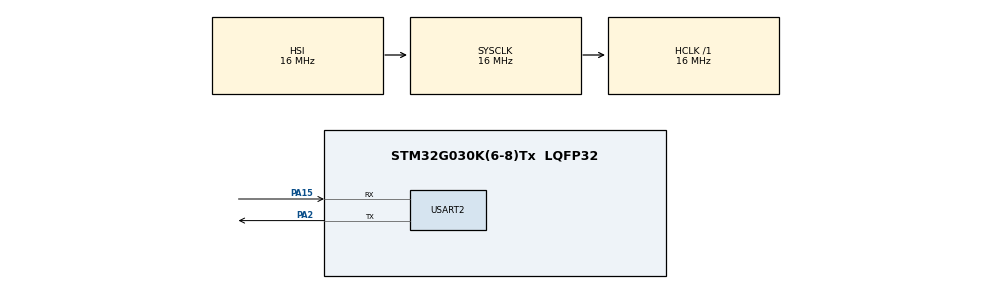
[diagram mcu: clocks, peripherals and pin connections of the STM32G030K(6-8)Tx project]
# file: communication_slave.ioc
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Dma.Request0=USART2_RX
Dma.USART2_RX.0.Direction=DMA_PERIPH_TO_MEMORY
Dma.USART2_RX.0.EventEnable=DISABLE
Dma.USART2_RX.0.Instance=DMA1_Channel1
Dma.USART2_RX.0.MemDataAlignment=DMA_MDATAALIGN_BYTE
Dma.USART2_RX.0.MemInc=DMA_MINC_ENABLE
Dma.USART2_RX.0.Mode=DMA_CIRCULAR
Dma.USART2_RX.0.PeriphDataAlignment=DMA_PDATAALIGN_BYTE
Dma.USART2_RX.0.PeriphInc=DMA_PINC_DISABLE
Dma.USART2_RX.0.Polarity=HAL_DMAMUX_REQ_GEN_RISING
Dma.USART2_RX.0.Priority=DMA_PRIORITY_HIGH
Dma.USART2_RX.0.RequestNumber=1
Dma.USART2_RX.0.SignalID=NONE
Dma.USART2_RX.0.SyncEnable=DISABLE
Dma.USART2_RX.0.SyncPolarity=HAL_DMAMUX_SYNC_NO_EVENT
Dma.USART2_RX.0.SyncRequestNumber=1
Dma.USART2_RX.0.SyncSignalID=NONE
Mcu.Family=STM32G0
Mcu.Name=STM32G030K(6-8)Tx
Mcu.Package=LQFP32
NVIC.DMA1_Channel1_IRQn=true\:0\:0\:false\:false\:true\:false\:true\:true
PA15.Mode=Asynchronous
PA15.Signal=USART2_RX
PA2.Mode=Asynchronous
PA2.Signal=USART2_TX
ProjectManager.HeapSize=0x200
ProjectManager.StackSize=0x400
ProjectManager.TargetToolchain=STM32CubeIDE
RCC.AHBFreq_Value=16000000
RCC.CortexFreq_Value=16000000
RCC.EXTERNAL_CLOCK_VALUE=12288000
RCC.HCLKFreq_Value=16000000
RCC.HSE_VALUE=8000000
RCC.HSI_VALUE=16000000
RCC.LSE_VALUE=32768
RCC.SYSCLKFreq_VALUE=16000000
RCC.VCOOutputFreq_Value=128000000
USART2.VirtualMode-Asynchronous=VM_ASYNC
board=custom

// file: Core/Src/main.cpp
/* USER CODE BEGIN Header */
/**
  ******************************************************************************
  * @file           : main.c
  * @brief          : Main program body
  ******************************************************************************
  * @attention
  *
  * Copyright (c) 2024 STMicroelectronics.
  * All rights reserved.
  *
  * This software is licensed under terms that can be found in the LICENSE file
  * in the root directory of this software component.
  * If no LICENSE file comes with this software, it is provided AS-IS.
  *
  ******************************************************************************
  */
/* USER CODE END Header */
#include "main.h"

UART_HandleTypeDef huart2;
DMA_HandleTypeDef hdma_usart2_rx;

/* USER CODE BEGIN PV */
static uint8_t rxBuf[128];
uint8_t receiveArray[11] = {0};
uint8_t read[6] = {0};
uint16_t angle = 0;
uint8_t speed = 0;

/* USER CODE END PV */

void SystemClock_Config(void);
static void MX_GPIO_Init(void);
static void MX_DMA_Init(void);
static void MX_USART2_UART_Init(void);
/* USER CODE BEGIN PFP */
void receiveData();

/* USER CODE END PFP */

int main(void)
{

  /* MCU Configuration--------------------------------------------------------*/

  /* Reset of all peripherals, Initializes the Flash interface and the Systick. */
  HAL_Init();

  /* Configure the system clock */
  SystemClock_Config();

  /* Initialize all configured peripherals */
  MX_GPIO_Init();
  MX_DMA_Init();
  MX_USART2_UART_Init();
  /* USER CODE BEGIN 2 */
  HAL_UART_Receive_DMA(&huart2, rxBuf, sizeof(rxBuf));

  /* USER CODE END 2 */

  /* Infinite loop */
  while (1)
  {

    /* USER CODE BEGIN 3 */
	  receiveData();

  }
  /* USER CODE END 3 */
}

void SystemClock_Config(void)
{
  RCC_OscInitTypeDef RCC_OscInitStruct = {0};
  RCC_ClkInitTypeDef RCC_ClkInitStruct = {0};

  /** Configure the main internal regulator output voltage
  */
  HAL_PWREx_ControlVoltageScaling(PWR_REGULATOR_VOLTAGE_SCALE1);

  /** Initializes the RCC Oscillators according to the specified parameters
  * in the RCC_OscInitTypeDef structure.
  */
  RCC_OscInitStruct.OscillatorType = RCC_OSCILLATORTYPE_HSI;
  RCC_OscInitStruct.HSIState = RCC_HSI_ON;
  RCC_OscInitStruct.HSIDiv = RCC_HSI_DIV1;
  RCC_OscInitStruct.HSICalibrationValue = RCC_HSICALIBRATION_DEFAULT;
  RCC_OscInitStruct.PLL.PLLState = RCC_PLL_NONE;
  if (HAL_RCC_OscConfig(&RCC_OscInitStruct) != HAL_OK)
  {
    Error_Handler();
  }

  /** Initializes the CPU, AHB and APB buses clocks
  */
  RCC_ClkInitStruct.ClockType = RCC_CLOCKTYPE_HCLK|RCC_CLOCKTYPE_SYSCLK
                              |RCC_CLOCKTYPE_PCLK1;
  RCC_ClkInitStruct.SYSCLKSource = RCC_SYSCLKSOURCE_HSI;
  RCC_ClkInitStruct.AHBCLKDivider = RCC_SYSCLK_DIV1;
  RCC_ClkInitStruct.APB1CLKDivider = RCC_HCLK_DIV1;

  if (HAL_RCC_ClockConfig(&RCC_ClkInitStruct, FLASH_LATENCY_0) != HAL_OK)
  {
    Error_Handler();
  }
}

static void MX_USART2_UART_Init(void)
{

  huart2.Instance = USART2;
  huart2.Init.BaudRate = 115200;
  huart2.Init.WordLength = UART_WORDLENGTH_8B;
  huart2.Init.StopBits = UART_STOPBITS_1;
  huart2.Init.Parity = UART_PARITY_NONE;
  huart2.Init.Mode = UART_MODE_TX_RX;
  huart2.Init.HwFlowCtl = UART_HWCONTROL_NONE;
  huart2.Init.OverSampling = UART_OVERSAMPLING_16;
  huart2.Init.OneBitSampling = UART_ONE_BIT_SAMPLE_DISABLE;
  huart2.Init.ClockPrescaler = UART_PRESCALER_DIV1;
  huart2.AdvancedInit.AdvFeatureInit = UART_ADVFEATURE_NO_INIT;
  if (HAL_UART_Init(&huart2) != HAL_OK)
  {
    Error_Handler();
  }

}

static void MX_DMA_Init(void)
{

  /* DMA controller clock enable */
  __HAL_RCC_DMA1_CLK_ENABLE();

  /* DMA interrupt init */
  /* DMA1_Channel1_IRQn interrupt configuration */
  HAL_NVIC_SetPriority(DMA1_Channel1_IRQn, 0, 0);
  HAL_NVIC_EnableIRQ(DMA1_Channel1_IRQn);

}

static void MX_GPIO_Init(void)
{

  /* GPIO Ports Clock Enable */
  __HAL_RCC_GPIOA_CLK_ENABLE();

}

/* USER CODE BEGIN 4 */
void receiveData(){
	uint8_t checksum = 0;
	static uint8_t index = 0;

  index = huart2.hdmarx->Instance->CNDTR;
  index = sizeof(rxBuf) - index;

  if (index >= 11)
  {
    for (int i = 0; i < 11; i++)
    {
      receiveArray[i] = rxBuf[index - 10 + i];
      HAL_Delay(1);
    }
  }

  for (int i = 0; i < 11; i++)
  {
    if (receiveArray[i] == 255 && receiveArray[i + 1] == 255)
    {
      for (int j = 0; j < 6; j++)
      {
        read[j] = receiveArray[i + j];
      }
    }
  }

  for (int i = 2; i < 5; i++)
  {
    checksum += read[i];
  }
  checksum += 10;
  checksum %= 256;

  if (read[5] == checksum)
  {
	  angle = read[2] * 256 + read[3];
	  speed = read[4];
  }
}

/* USER CODE END 4 */

void Error_Handler(void)
{
  __disable_irq();
  while (1)
  {
  }
}
